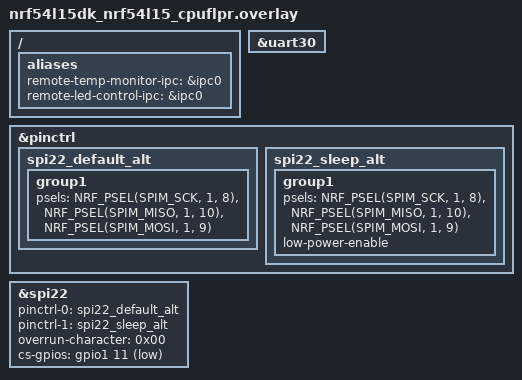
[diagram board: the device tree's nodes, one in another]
/*
 * Copyright (c) 2026 Nordic Semiconductor ASA
 *
 * SPDX-License-Identifier: LicenseRef-Nordic-5-Clause
 */

/ {
	aliases {
		remote-temp-monitor-ipc = &ipc0;
		remote-led-control-ipc = &ipc0;
	};
};

&uart30 {
	/delete-property/ hw-flow-control;
};

&pinctrl {
	spi22_default_alt: spi22_default_alt {
		group1 {
			psels = <NRF_PSEL(SPIM_SCK, 1, 8)>,
				<NRF_PSEL(SPIM_MISO, 1, 10)>,
				<NRF_PSEL(SPIM_MOSI, 1, 9)>;
		};
	};

	spi22_sleep_alt: spi22_sleep_alt {
		group1 {
			psels = <NRF_PSEL(SPIM_SCK, 1, 8)>,
				<NRF_PSEL(SPIM_MISO, 1, 10)>,
				<NRF_PSEL(SPIM_MOSI, 1, 9)>;
			low-power-enable;
		};
	};
};

app_spi: &spi22 {
	status = "okay";
	pinctrl-0 = <&spi22_default_alt>;
	pinctrl-1 = <&spi22_sleep_alt>;
	pinctrl-names = "default", "sleep";
	overrun-character = <0x00>;
	cs-gpios = <&gpio1 11 GPIO_ACTIVE_LOW>;
};
